# AT32F405 register map
Vendor: Keil; Series: AT32F405; File version: 1.0
CPU: CM4 r0p1, little endian, no MPU, FPU, 4 interrupt priority bits
Registers are 32-bit, read-write, reset 0x0 unless marked. A register's access mark holds for its fields unless they carry their own. Offsets are from the block's base; [hi:lo] are bit positions; {n}, {i} and the like mark numbered series.

## USB_OTG1_PWRCLK — USB on the go full speed
Base 0x50000E00
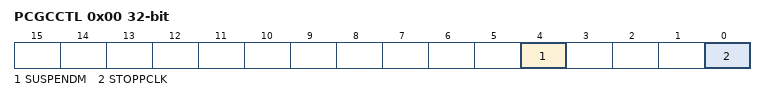
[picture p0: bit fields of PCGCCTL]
0x00 PCGCCTL — OTGFS power and clock gating control register (OTGFS_PCGCCTL)
  [4] SUSPENDM ro — PHY Suspended
  [0] STOPPCLK — Stop PHY clock

## USB_OTGHS_PWRCLK — USB on the go high speed
Base 0x40040E00
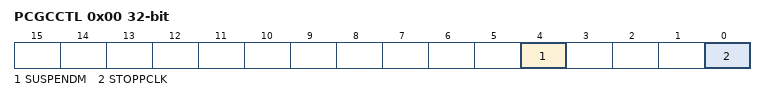
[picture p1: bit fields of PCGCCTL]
0x00 PCGCCTL — OTGHS power and clock gating control register (OTGHS_PCGCCTL)
  [4] SUSPENDM ro — PHY Suspended
  [0] STOPPCLK — Stop PHY clock

## SCFG — System configuration controller
Base 0x40013800
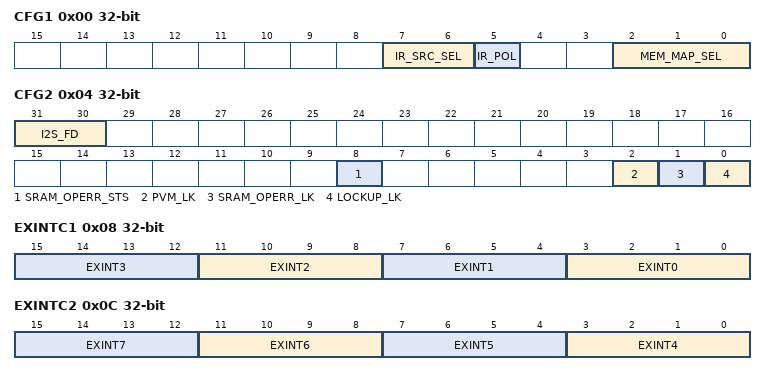
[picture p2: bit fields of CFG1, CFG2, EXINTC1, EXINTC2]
0x00 CFG1 — configuration register 1
  [7:6] IR_SRC_SEL — IR signal source selection
  [5] IR_POL — IR output polarity selection
  [2:0] MEM_MAP_SEL — Memory address mapping selection bits
0x04 CFG2 — configuration register 2
  [31:30] I2S_FD — I2S full duplex config
  [8] SRAM_OPERR_STS — SRAM odd parity error status
  [2] PVM_LK — PVM lock enable
  [1] SRAM_OPERR_LK — SRAM odd parity error lock enable
  [0] LOCKUP_LK — CM4F LOCKUP bit enable
0x08 EXINTC1 — external interrupt configuration register 1
  [4n+3:4n] EXINT{n} (n=0..3) — EXINT {n} configuration bits
0x0C EXINTC2 — external interrupt configuration register 2
  [4n-13:4n-16] EXINT{n} (n=4..7) — EXINT {n} configuration bits
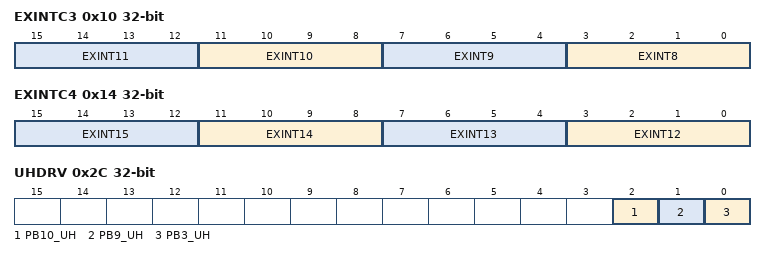
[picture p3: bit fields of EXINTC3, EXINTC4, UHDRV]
0x10 EXINTC3 — external interrupt configuration register 3
  [4n-29:4n-32] EXINT{n} (n=8..11) — EXINT {n} configuration bits
0x14 EXINTC4 — external interrupt configuration register 4
  [4n-45:4n-48] EXINT{n} (n=12..15) — EXINT {n} configuration bits
0x2C UHDRV — Ultra high drive register
  [2] PB10_UH — PB10 ultra high sourcing/sinking strength
  [1] PB9_UH — PB9 ultra high sourcing/sinking strength
  [0] PB3_UH — PB3 ultra high sourcing/sinking strength

## QSPI1 — Quad SPI Controller
Base 0xA0001000
0x00 CMD_W0 — Command word 0
  [31:0] SPIADR — SPI flash address
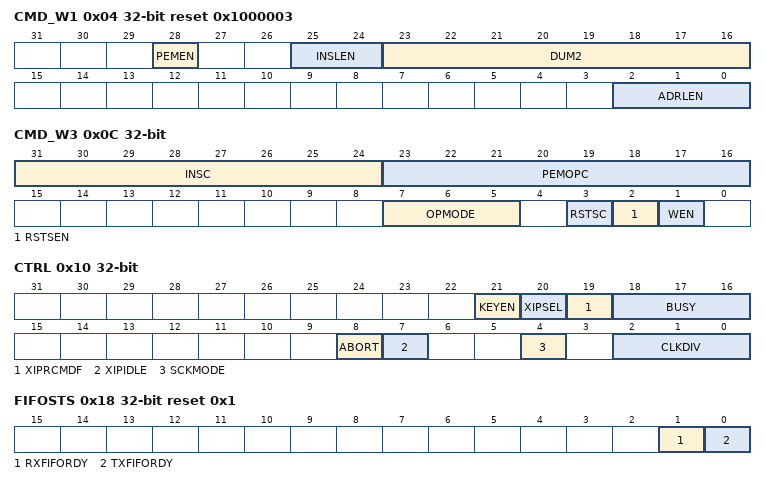
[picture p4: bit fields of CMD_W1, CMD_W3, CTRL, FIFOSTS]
0x04 CMD_W1 reset 0x1000003 — Command word 1
  [28] PEMEN — Perfrmance enhance mode enable
  [25:24] INSLEN — Instruction code length
  [23:16] DUM2 — Second dummy state cycle
  [2:0] ADRLEN — SPI address length
0x08 CMD_W2 reset 0x1000003 — Command word 2
  [31:0] DCNT — Read write data counter
0x0C CMD_W3 — Command word 3
  [31:24] INSC — Instruction code
  [23:16] PEMOPC — Performance enhance mode operate code
  [7:5] OPMODE — SPI operate mode
  [3] RSTSC — Read spi status configure
  [2] RSTSEN — Read spi status enable
  [1] WEN — Write data enable
0x10 CTRL — Control register
  [21] KEYEN — encryption key enable
  [20] XIPSEL — XIP port selection
  [19] XIPRCMDF — XIP read command flush
  [18:16] BUSY — Busy bit of spi status
  [8] ABORT — Abort instruction
  [7] XIPIDLE — XIP port idle status
  [4] SCKMODE — Sckout mode
  [2:0] CLKDIV — SPI clock divider
0x18 FIFOSTS ro reset 0x1 — FIFO Status register
  [1] RXFIFORDY — RxFIFO ready status
  [0] TXFIFORDY — TxFIFO ready status
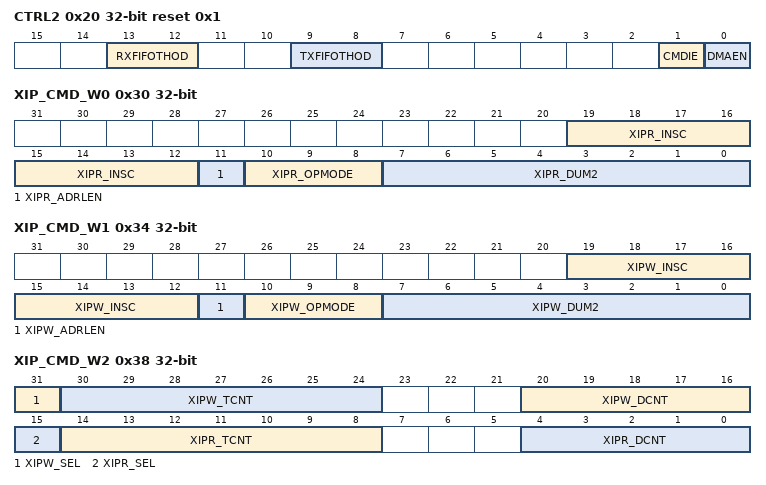
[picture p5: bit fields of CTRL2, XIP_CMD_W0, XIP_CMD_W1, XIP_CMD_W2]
0x20 CTRL2 reset 0x1 — control register 2
  [13:12] RXFIFOTHOD
  [9:8] TXFIFOTHOD
  [1] CMDIE — Command complete interrupt enable
  [0] DMAEN — DMA handshake enable
0x24 CMDSTS ro — CMD status register
  [0] CMDSTS — Command complete status
0x28 RSTS ro — SPI read status register
  [7:0] SPISTS — SPI read status
0x2C FSIZE — SPI flash size
  [31:0] SPIFSIZE
0x30 XIP_CMD_W0 — XIP command word 0
  [19:12] XIPR_INSC — XIP read instruction code
  [11] XIPR_ADRLEN — XIP read address length
  [10:8] XIPR_OPMODE — XIP read operate mode
  [7:0] XIPR_DUM2 — XIP read second dummy cycle
0x34 XIP_CMD_W1 — XIP command word 1
  [19:12] XIPW_INSC — XIP write instruction code
  [11] XIPW_ADRLEN — XIP write address length
  [10:8] XIPW_OPMODE — XIP write operate mode
  [7:0] XIPW_DUM2 — XIP write second dummy cycle
0x38 XIP_CMD_W2 — XIP command word 2
  [31] XIPW_SEL — XIP write continue mode select
  [30:24] XIPW_TCNT — XIP continue write cycle counter
  [20:16] XIPW_DCNT — XIP write data counter
  [15] XIPR_SEL — XIP read continue mode select
  [14:8] XIPR_TCNT — XIP continue read cycle counter
  [4:0] XIPR_DCNT — XIP read data counter
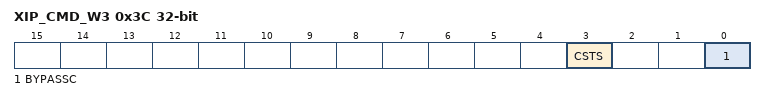
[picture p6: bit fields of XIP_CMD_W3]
0x3C XIP_CMD_W3 — XIP command word 3
  [3] CSTS — Cache status
  [0] BYPASSC — Bypass cache function
0x40 CTRL3 — control register 3
  [8] ISPC — Input sampling phase correction enable
0x50 REV reset 0x10500 — Revision
  [30:0] REVISION — Revision number
0x100 DT — 32/16/8 bit data port register

## FPU — Floting point unit
Base 0xE000EF34
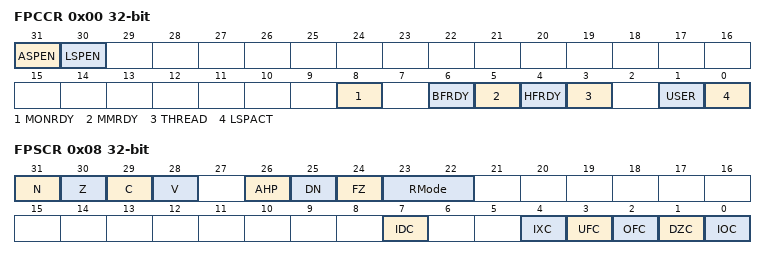
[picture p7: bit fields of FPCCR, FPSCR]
0x00 FPCCR — Floating-point context control register
  [31] ASPEN, [30] LSPEN, [8] MONRDY, [6] BFRDY, [5] MMRDY, [4] HFRDY, [3] THREAD, [1] USER, [0] LSPACT
0x04 FPCAR — Floating-point context address register
  [31:3] ADDRESS — Location of unpopulated floating-point
0x08 FPSCR — Floating-point status control register
  [31] N — Negative condition code flag
  [30] Z — Zero condition code flag
  [29] C — Carry condition code flag
  [28] V — Overflow condition code flag
  [26] AHP — Alternative half-precision control bit
  [25] DN — Default NaN mode control bit
  [24] FZ — Flush-to-zero mode control bit:
  [23:22] RMode — Rounding Mode control field
  [7] IDC — Input denormal cumulative exception bit.
  [4] IXC — Inexact cumulative exception bit
  [3] UFC — Underflow cumulative exception bit
  [2] OFC — Overflow cumulative exception bit
  [1] DZC — Division by zero cumulative exception bit.
  [0] IOC — Invalid operation cumulative exception bit
